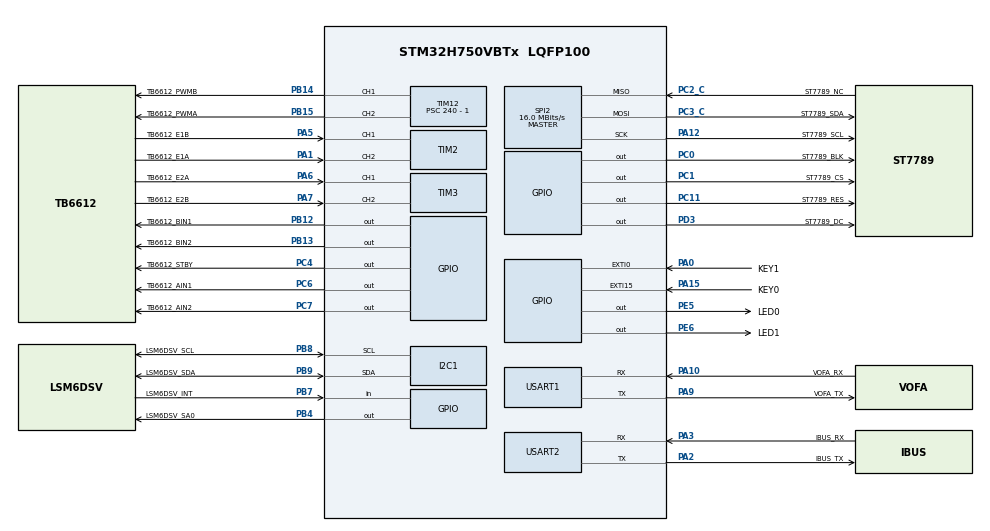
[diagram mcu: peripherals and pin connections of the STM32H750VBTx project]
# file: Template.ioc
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CORTEX_M7.BaseAddress-Cortex_Memory_Protection_Unit_Region0_Settings=0x2400000
CORTEX_M7.CPU_DCache=Disabled
CORTEX_M7.CPU_ICache=Disabled
CORTEX_M7.Enable-Cortex_Memory_Protection_Unit_Region0_Settings=MPU_REGION_ENABLE
CORTEX_M7.IsCacheable-Cortex_Memory_Protection_Unit_Region0_Settings=MPU_ACCESS_CACHEABLE
CORTEX_M7.IsShareable-Cortex_Memory_Protection_Unit_Region0_Settings=MPU_ACCESS_SHAREABLE
CORTEX_M7.MPU_Control=__NULL
CORTEX_M7.Size-Cortex_Memory_Protection_Unit_Region0_Settings=MPU_REGION_SIZE_512KB
CORTEX_M7.default_mode_Activation=0
Dma.Request0=SPI2_TX
Dma.Request1=SPI2_RX
Dma.SPI2_RX.1.Direction=DMA_PERIPH_TO_MEMORY
Dma.SPI2_RX.1.EventEnable=DISABLE
Dma.SPI2_RX.1.FIFOMode=DMA_FIFOMODE_DISABLE
Dma.SPI2_RX.1.Instance=DMA1_Stream1
Dma.SPI2_RX.1.MemDataAlignment=DMA_MDATAALIGN_BYTE
Dma.SPI2_RX.1.MemInc=DMA_MINC_ENABLE
Dma.SPI2_RX.1.Mode=DMA_NORMAL
Dma.SPI2_RX.1.PeriphDataAlignment=DMA_PDATAALIGN_BYTE
Dma.SPI2_RX.1.PeriphInc=DMA_PINC_DISABLE
Dma.SPI2_RX.1.Polarity=HAL_DMAMUX_REQ_GEN_RISING
Dma.SPI2_RX.1.Priority=DMA_PRIORITY_LOW
Dma.SPI2_RX.1.RequestNumber=1
Dma.SPI2_RX.1.SignalID=NONE
Dma.SPI2_RX.1.SyncEnable=DISABLE
Dma.SPI2_RX.1.SyncPolarity=HAL_DMAMUX_SYNC_NO_EVENT
Dma.SPI2_RX.1.SyncRequestNumber=1
Dma.SPI2_RX.1.SyncSignalID=NONE
Dma.SPI2_TX.0.Direction=DMA_MEMORY_TO_PERIPH
Dma.SPI2_TX.0.EventEnable=DISABLE
Dma.SPI2_TX.0.FIFOMode=DMA_FIFOMODE_DISABLE
Dma.SPI2_TX.0.Instance=DMA1_Stream0
Dma.SPI2_TX.0.MemDataAlignment=DMA_MDATAALIGN_BYTE
Dma.SPI2_TX.0.MemInc=DMA_MINC_ENABLE
Dma.SPI2_TX.0.Mode=DMA_NORMAL
Dma.SPI2_TX.0.PeriphDataAlignment=DMA_PDATAALIGN_BYTE
Dma.SPI2_TX.0.PeriphInc=DMA_PINC_DISABLE
Dma.SPI2_TX.0.Polarity=HAL_DMAMUX_REQ_GEN_RISING
Dma.SPI2_TX.0.Priority=DMA_PRIORITY_LOW
Dma.SPI2_TX.0.RequestNumber=1
Dma.SPI2_TX.0.SignalID=NONE
Dma.SPI2_TX.0.SyncEnable=DISABLE
Dma.SPI2_TX.0.SyncPolarity=HAL_DMAMUX_SYNC_NO_EVENT
Dma.SPI2_TX.0.SyncRequestNumber=1
Dma.SPI2_TX.0.SyncSignalID=NONE
FREERTOS.Tasks01=defaultTask,8,256,StartDefaultTask,Default,NULL,Dynamic,NULL,NULL;LightTask,8,128,StartLightTask,As weak,NULL,Dynamic,NULL,NULL;AttitudeTask,46,512,StartAttitudeTask,As weak,NULL,Dynamic,NULL,NULL;DisplayTask,8,256,StartDisplayTask,As weak,NULL,Dynamic,NULL,NULL;MotorTask,44,256,StartMotorTask,As weak,NULL,Dynamic,NULL,NULL;SpeedControlTas,45,256,StartSpeedControlTask,As weak,NULL,Dynamic,NULL,NULL;AngleControlTas,47,256,StartAngleControlTask,As weak,NULL,Dynamic,NULL,NULL;AngVelControlTa,48,256,StartAngVelControlTask,As weak,NULL,Dynamic,NULL,NULL;RemoteTask,24,256,StartRemoteTask,As weak,NULL,Dynamic,NULL,NULL
FREERTOS.configENABLE_FPU=1
I2C1.Timing=0x307075B1
Mcu.Family=STM32H7
Mcu.Name=STM32H750VBTx
Mcu.Package=LQFP100
NVIC.DMA1_Stream0_IRQn=true\:5\:0\:false\:false\:true\:true\:false\:true\:true
NVIC.DMA1_Stream1_IRQn=true\:5\:0\:false\:false\:true\:true\:false\:true\:true
NVIC.EXTI0_IRQn=true\:11\:0\:true\:false\:true\:true\:true\:true\:true
NVIC.EXTI15_10_IRQn=true\:11\:0\:true\:false\:true\:true\:true\:true\:true
NVIC.PriorityGroup=NVIC_PRIORITYGROUP_4
NVIC.SPI2_IRQn=true\:5\:0\:false\:false\:true\:true\:false\:true\:true
NVIC.TIM7_IRQn=true\:15\:0\:false\:false\:true\:false\:false\:true\:true
NVIC.TimeBase=TIM7_IRQn
NVIC.TimeBaseIP=TIM7
NVIC.USART1_IRQn=true\:5\:0\:false\:false\:true\:true\:true\:true\:true
NVIC.USART2_IRQn=true\:5\:0\:false\:false\:true\:true\:true\:true\:true
PA0.GPIO_Label=KEY1
PA0.GPIO_PuPd=GPIO_PULLDOWN
PA0.Signal=GPXTI0
PA1.GPIO_Label=TB6612_E1A
PA1.Signal=S_TIM2_CH2
PA10.GPIO_Label=VOFA_RX
PA10.GPIO_Speed=GPIO_SPEED_FREQ_VERY_HIGH
PA10.Mode=Asynchronous
PA10.Signal=USART1_RX
PA12.GPIO_Label=ST7789_SCL
PA12.Mode=Full_Duplex_Master
PA12.Signal=SPI2_SCK
PA13\ (JTMS/SWDIO).GPIO_Label=DAP_SWD
PA13\ (JTMS/SWDIO).Mode=Serial_Wire
PA13\ (JTMS/SWDIO).Signal=DEBUG_JTMS-SWDIO
PA14\ (JTCK/SWCLK).GPIO_Label=DAP_SCK
PA14\ (JTCK/SWCLK).Mode=Serial_Wire
PA14\ (JTCK/SWCLK).Signal=DEBUG_JTCK-SWCLK
PA15\ (JTDI).GPIO_Label=KEY0
PA15\ (JTDI).GPIO_PuPd=GPIO_PULLDOWN
PA15\ (JTDI).Signal=GPXTI15
PA2.GPIO_Label=IBUS_TX
PA2.Mode=Asynchronous
PA2.Signal=USART2_TX
PA3.GPIO_Label=IBUS_RX
PA3.GPIO_PuPd=GPIO_PULLUP
PA3.GPIO_Speed=GPIO_SPEED_FREQ_VERY_HIGH
PA3.Mode=Asynchronous
PA3.Signal=USART2_RX
PA5.GPIO_Label=TB6612_E1B
PA5.Signal=S_TIM2_CH1_ETR
PA6.GPIO_Label=TB6612_E2A
PA6.Signal=S_TIM3_CH1
PA7.GPIO_Label=TB6612_E2B
PA7.Signal=S_TIM3_CH2
PA9.GPIO_Label=VOFA_TX
PA9.GPIO_Speed=GPIO_SPEED_FREQ_VERY_HIGH
PA9.Mode=Asynchronous
PA9.Signal=USART1_TX
PB12.GPIO_Label=TB6612_BIN1
PB12.Signal=GPIO_Output
PB13.GPIO_Label=TB6612_BIN2
PB13.Signal=GPIO_Output
PB14.GPIO_Label=TB6612_PWMB
PB14.Signal=S_TIM12_CH1
PB15.GPIO_Label=TB6612_PWMA
PB15.Signal=S_TIM12_CH2
PB4\ (NJTRST).GPIO_Label=LSM6DSV_SA0
PB4\ (NJTRST).GPIO_PuPd=GPIO_PULLDOWN
PB4\ (NJTRST).PinState=GPIO_PIN_SET
PB4\ (NJTRST).Signal=GPIO_Output
PB7.GPIO_Label=LSM6DSV_INT
PB7.GPIO_PuPd=GPIO_PULLDOWN
PB7.Signal=GPIO_Input
PB8.GPIO_Label=LSM6DSV_SCL
PB8.GPIO_Mode=GPIO_MODE_AF_OD
PB8.GPIO_Pu=GPIO_PULLUP
PB8.GPIO_Speed=GPIO_SPEED_FREQ_VERY_HIGH
PB8.Mode=I2C
PB8.Signal=I2C1_SCL
PB9.GPIO_Label=LSM6DSV_SDA
PB9.GPIO_Mode=GPIO_MODE_AF_OD
PB9.GPIO_Pu=GPIO_PULLUP
PB9.GPIO_Speed=GPIO_SPEED_FREQ_VERY_HIGH
PB9.Mode=I2C
PB9.Signal=I2C1_SDA
PC0.GPIO_Label=ST7789_BLK
PC0.Signal=GPIO_Output
PC1.GPIO_Label=ST7789_CS
PC1.Signal=GPIO_Output
PC11.GPIO_Label=ST7789_RES
PC11.Signal=GPIO_Output
PC2_C.GPIO_Label=ST7789_NC
PC2_C.Mode=Full_Duplex_Master
PC2_C.Signal=SPI2_MISO
PC3_C.GPIO_Label=ST7789_SDA
PC3_C.Mode=Full_Duplex_Master
PC3_C.Signal=SPI2_MOSI
PC4.GPIO_Label=TB6612_STBY
PC4.Signal=GPIO_Output
PC6.GPIO_Label=TB6612_AIN1
PC6.Signal=GPIO_Output
PC7.GPIO_Label=TB6612_AIN2
PC7.Signal=GPIO_Output
PD3.GPIO_Label=ST7789_DC
PD3.Signal=GPIO_Output
PE5.GPIO_Label=LED0
PE5.GPIO_PuPd=GPIO_PULLDOWN
PE5.Signal=GPIO_Output
PE6.GPIO_Label=LED1
PE6.GPIO_PuPd=GPIO_PULLDOWN
PE6.Signal=GPIO_Output
PH0-OSC_IN\ (PH0).GPIO_Label=OSC_IN
PH0-OSC_IN\ (PH0).Mode=HSE-External-Oscillator
PH0-OSC_IN\ (PH0).Signal=RCC_OSC_IN
PH1-OSC_OUT\ (PH1).GPIO_Label=OSC_OUT
PH1-OSC_OUT\ (PH1).Mode=HSE-External-Oscillator
PH1-OSC_OUT\ (PH1).Signal=RCC_OSC_OUT
ProjectManager.HeapSize=0x2000
ProjectManager.StackSize=0x4000
ProjectManager.TargetToolchain=MDK-ARM V5.32
RCC.ADCFreq_Value=16125000
RCC.APB1Freq_Value=120000000
RCC.APB2Freq_Value=120000000
RCC.APB3Freq_Value=120000000
RCC.APB4Freq_Value=120000000
RCC.CortexFreq_Value=480000000
RCC.D1PPRE=RCC_APB3_DIV2
RCC.D2PPRE1=RCC_APB1_DIV2
RCC.D2PPRE2=RCC_APB2_DIV2
RCC.D3PPRE=RCC_APB4_DIV2
RCC.DIVM1=1
RCC.DIVN1=120
RCC.HCLKFreq_Value=240000000
RCC.HPRE=RCC_HCLK_DIV2
RCC.HSE_VALUE=8000000
RCC.PLL2FRACN=0
RCC.PLL3FRACN=0
RCC.PLLFRACN=0
RCC.PLLSourceVirtual=RCC_PLLSOURCE_HSE
RCC.SPI123CLockSelection=RCC_SPI123CLKSOURCE_CLKP
RCC.SYSCLKFreq_VALUE=480000000
RCC.SYSCLKSource=RCC_SYSCLKSOURCE_PLLCLK
RCC.USBFreq_Value=480000000
SH.S_TIM12_CH1.0=TIM12_CH1,PWM Generation1 CH1
SH.S_TIM12_CH2.0=TIM12_CH2,PWM Generation2 CH2
SH.S_TIM2_CH1_ETR.0=TIM2_CH1,Encoder_Interface
SH.S_TIM2_CH2.0=TIM2_CH2,Encoder_Interface
SH.S_TIM3_CH1.0=TIM3_CH1,Encoder_Interface
SH.S_TIM3_CH2.0=TIM3_CH2,Encoder_Interface
SPI2.BaudRatePrescaler=SPI_BAUDRATEPRESCALER_4
SPI2.CLKPolarity=SPI_POLARITY_HIGH
SPI2.CalculateBaudRate=16.0 MBits/s
SPI2.DataSize=SPI_DATASIZE_8BIT
SPI2.Direction=SPI_DIRECTION_2LINES
SPI2.Mode=SPI_MODE_MASTER
SPI2.VirtualType=VM_MASTER
TIM12.Channel-PWM\ Generation1\ CH1=TIM_CHANNEL_1
TIM12.Channel-PWM\ Generation2\ CH2=TIM_CHANNEL_2
TIM12.Prescaler=240 - 1
TIM15.Prescaler=240 - 1
USART1.VirtualMode-Asynchronous=VM_ASYNC
USART2.VirtualMode-Asynchronous=VM_ASYNC
VP_FREERTOS_VS_CMSIS_V2.Mode=CMSIS_V2
VP_MEMORYMAP_VS_MEMORYMAP.Mode=CurAppReg
VP_SYS_VS_tim7.Mode=TIM7
VP_TIM12_VS_ClockSourceINT.Mode=Internal
VP_TIM15_VS_ClockSourceINT.Mode=Internal
board=custom

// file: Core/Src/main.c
/* USER CODE BEGIN Header */
/**
  ******************************************************************************
  * @file           : main.c
  * @brief          : Main program body
  ******************************************************************************
  * @attention
  *
  * Copyright (c) 2025 STMicroelectronics.
  * All rights reserved.
  *
  * This software is licensed under terms that can be found in the LICENSE file
  * in the root directory of this software component.
  * If no LICENSE file comes with this software, it is provided AS-IS.
  *
  ******************************************************************************
  */
/* USER CODE END Header */
#include "main.h"
#include "cmsis_os.h"
#include "dma.h"
#include "i2c.h"
#include "spi.h"
#include "tim.h"
#include "usart.h"
#include "gpio.h"

/* USER CODE BEGIN Includes */
#include "stdio.h"
/* USER CODE END Includes */

void SystemClock_Config(void);
void PeriphCommonClock_Config(void);
void MX_FREERTOS_Init(void);
/* USER CODE BEGIN PFP */
void UART1_UserCallback(void *device_instance, uint16_t size);
/* USER CODE END PFP */

int main(void)
{

  /* MCU Configuration--------------------------------------------------------*/

  /* Reset of all peripherals, Initializes the Flash interface and the Systick. */
  HAL_Init();

  /* Configure the system clock */
  SystemClock_Config();

  /* Configure the peripherals common clocks */
  PeriphCommonClock_Config();

  /* Initialize all configured peripherals */
  MX_GPIO_Init();
  MX_DMA_Init();
  MX_USART1_UART_Init();
  MX_I2C1_Init();
  MX_TIM2_Init();
  MX_TIM3_Init();
  MX_TIM12_Init();
  MX_TIM15_Init();
  MX_SPI2_Init();
  MX_USART2_UART_Init();

  /* Init scheduler */
  osKernelInitialize();  /* Call init function for freertos objects (in cmsis_os2.c) */
  MX_FREERTOS_Init();

  /* Start scheduler */
  osKernelStart();

  /* We should never get here as control is now taken by the scheduler */

  /* Infinite loop */
  /* USER CODE BEGIN WHILE */
  while (1)
  {
    HAL_Delay(50);
    /* USER CODE END WHILE */

  }
}

void SystemClock_Config(void)
{
  RCC_OscInitTypeDef RCC_OscInitStruct = {0};
  RCC_ClkInitTypeDef RCC_ClkInitStruct = {0};

  /** Supply configuration update enable
  */
  HAL_PWREx_ConfigSupply(PWR_LDO_SUPPLY);

  /** Configure the main internal regulator output voltage
  */
  __HAL_PWR_VOLTAGESCALING_CONFIG(PWR_REGULATOR_VOLTAGE_SCALE0);

  while(!__HAL_PWR_GET_FLAG(PWR_FLAG_VOSRDY)) {}

  /** Initializes the RCC Oscillators according to the specified parameters
  * in the RCC_OscInitTypeDef structure.
  */
  RCC_OscInitStruct.OscillatorType = RCC_OSCILLATORTYPE_HSI|RCC_OSCILLATORTYPE_HSE;
  RCC_OscInitStruct.HSEState = RCC_HSE_ON;
  RCC_OscInitStruct.HSIState = RCC_HSI_DIV1;
  RCC_OscInitStruct.HSICalibrationValue = RCC_HSICALIBRATION_DEFAULT;
  RCC_OscInitStruct.PLL.PLLState = RCC_PLL_ON;
  RCC_OscInitStruct.PLL.PLLSource = RCC_PLLSOURCE_HSE;
  RCC_OscInitStruct.PLL.PLLM = 1;
  RCC_OscInitStruct.PLL.PLLN = 120;
  RCC_OscInitStruct.PLL.PLLP = 2;
  RCC_OscInitStruct.PLL.PLLQ = 2;
  RCC_OscInitStruct.PLL.PLLR = 2;
  RCC_OscInitStruct.PLL.PLLRGE = RCC_PLL1VCIRANGE_3;
  RCC_OscInitStruct.PLL.PLLVCOSEL = RCC_PLL1VCOWIDE;
  RCC_OscInitStruct.PLL.PLLFRACN = 0;
  if (HAL_RCC_OscConfig(&RCC_OscInitStruct) != HAL_OK)
  {
    Error_Handler();
  }

  /** Initializes the CPU, AHB and APB buses clocks
  */
  RCC_ClkInitStruct.ClockType = RCC_CLOCKTYPE_HCLK|RCC_CLOCKTYPE_SYSCLK
                              |RCC_CLOCKTYPE_PCLK1|RCC_CLOCKTYPE_PCLK2
                              |RCC_CLOCKTYPE_D3PCLK1|RCC_CLOCKTYPE_D1PCLK1;
  RCC_ClkInitStruct.SYSCLKSource = RCC_SYSCLKSOURCE_PLLCLK;
  RCC_ClkInitStruct.SYSCLKDivider = RCC_SYSCLK_DIV1;
  RCC_ClkInitStruct.AHBCLKDivider = RCC_HCLK_DIV2;
  RCC_ClkInitStruct.APB3CLKDivider = RCC_APB3_DIV2;
  RCC_ClkInitStruct.APB1CLKDivider = RCC_APB1_DIV2;
  RCC_ClkInitStruct.APB2CLKDivider = RCC_APB2_DIV2;
  RCC_ClkInitStruct.APB4CLKDivider = RCC_APB4_DIV2;

  if (HAL_RCC_ClockConfig(&RCC_ClkInitStruct, FLASH_LATENCY_4) != HAL_OK)
  {
    Error_Handler();
  }
}

void PeriphCommonClock_Config(void)
{
  RCC_PeriphCLKInitTypeDef PeriphClkInitStruct = {0};

  /** Initializes the peripherals clock
  */
  PeriphClkInitStruct.PeriphClockSelection = RCC_PERIPHCLK_CKPER;
  PeriphClkInitStruct.CkperClockSelection = RCC_CLKPSOURCE_HSI;
  if (HAL_RCCEx_PeriphCLKConfig(&PeriphClkInitStruct) != HAL_OK)
  {
    Error_Handler();
  }
}

void HAL_TIM_PeriodElapsedCallback(TIM_HandleTypeDef *htim)
{
  if (htim->Instance == TIM7)
  {
    HAL_IncTick();
  }
}

void Error_Handler(void)
{
  __disable_irq();
  while (1)
  {
  }
}

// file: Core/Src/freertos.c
/* USER CODE BEGIN Header */
/**
  ******************************************************************************
  * File Name          : freertos.c
  * Description        : Code for freertos applications
  ******************************************************************************
  * @attention
  *
  * Copyright (c) 2025 STMicroelectronics.
  * All rights reserved.
  *
  * This software is licensed under terms that can be found in the LICENSE file
  * in the root directory of this software component.
  * If no LICENSE file comes with this software, it is provided AS-IS.
  *
  ******************************************************************************
  */
/* USER CODE END Header */

#include "FreeRTOS.h"
#include "task.h"
#include "main.h"
#include "cmsis_os.h"

/* USER CODE BEGIN Includes */
#include "task_control.h"
#include "stdio.h"
#include "usart.h"
#include "task_attitude.h"
#include "task_motor.h"
/* USER CODE END Includes */

/* Definitions for defaultTask */
osThreadId_t defaultTaskHandle;
const osThreadAttr_t defaultTask_attributes = {
  .name = "defaultTask",
  .stack_size = 256 * 4,
  .priority = (osPriority_t) osPriorityLow,
};
/* Definitions for LightTask */
osThreadId_t LightTaskHandle;
const osThreadAttr_t LightTask_attributes = {
  .name = "LightTask",
  .stack_size = 128 * 4,
  .priority = (osPriority_t) osPriorityLow,
};
/* Definitions for AttitudeTask */
osThreadId_t AttitudeTaskHandle;
const osThreadAttr_t AttitudeTask_attributes = {
  .name = "AttitudeTask",
  .stack_size = 512 * 4,
  .priority = (osPriority_t) osPriorityHigh6,
};
/* Definitions for DisplayTask */
osThreadId_t DisplayTaskHandle;
const osThreadAttr_t DisplayTask_attributes = {
  .name = "DisplayTask",
  .stack_size = 256 * 4,
  .priority = (osPriority_t) osPriorityLow,
};
/* Definitions for MotorTask */
osThreadId_t MotorTaskHandle;
const osThreadAttr_t MotorTask_attributes = {
  .name = "MotorTask",
  .stack_size = 256 * 4,
  .priority = (osPriority_t) osPriorityHigh4,
};
/* Definitions for SpeedControlTas */
osThreadId_t SpeedControlTasHandle;
const osThreadAttr_t SpeedControlTas_attributes = {
  .name = "SpeedControlTas",
  .stack_size = 256 * 4,
  .priority = (osPriority_t) osPriorityHigh5,
};
/* Definitions for AngleControlTas */
osThreadId_t AngleControlTasHandle;
const osThreadAttr_t AngleControlTas_attributes = {
  .name = "AngleControlTas",
  .stack_size = 256 * 4,
  .priority = (osPriority_t) osPriorityHigh7,
};
/* Definitions for AngVelControlTa */
osThreadId_t AngVelControlTaHandle;
const osThreadAttr_t AngVelControlTa_attributes = {
  .name = "AngVelControlTa",
  .stack_size = 256 * 4,
  .priority = (osPriority_t) osPriorityRealtime,
};
/* Definitions for RemoteTask */
osThreadId_t RemoteTaskHandle;
const osThreadAttr_t RemoteTask_attributes = {
  .name = "RemoteTask",
  .stack_size = 256 * 4,
  .priority = (osPriority_t) osPriorityNormal,
};

void StartDefaultTask(void *argument);
void StartLightTask(void *argument);
void StartAttitudeTask(void *argument);
void StartDisplayTask(void *argument);
void StartMotorTask(void *argument);
void StartSpeedControlTask(void *argument);
void StartAngleControlTask(void *argument);
void StartAngVelControlTask(void *argument);
void StartRemoteTask(void *argument);

void MX_FREERTOS_Init(void); /* (MISRA C 2004 rule 8.1) */

void MX_FREERTOS_Init(void) {

  /* Create the thread(s) */
  /* creation of defaultTask */
  defaultTaskHandle = osThreadNew(StartDefaultTask, NULL, &defaultTask_attributes);

  /* creation of LightTask */
  LightTaskHandle = osThreadNew(StartLightTask, NULL, &LightTask_attributes);

  /* creation of AttitudeTask */
  AttitudeTaskHandle = osThreadNew(StartAttitudeTask, NULL, &AttitudeTask_attributes);

  /* creation of DisplayTask */
  DisplayTaskHandle = osThreadNew(StartDisplayTask, NULL, &DisplayTask_attributes);

  /* creation of MotorTask */
  MotorTaskHandle = osThreadNew(StartMotorTask, NULL, &MotorTask_attributes);

  /* creation of SpeedControlTas */
  SpeedControlTasHandle = osThreadNew(StartSpeedControlTask, NULL, &SpeedControlTas_attributes);

  /* creation of AngleControlTas */
  AngleControlTasHandle = osThreadNew(StartAngleControlTask, NULL, &AngleControlTas_attributes);

  /* creation of AngVelControlTa */
  AngVelControlTaHandle = osThreadNew(StartAngVelControlTask, NULL, &AngVelControlTa_attributes);

  /* creation of RemoteTask */
  RemoteTaskHandle = osThreadNew(StartRemoteTask, NULL, &RemoteTask_attributes);

}

void StartDefaultTask(void *argument)
{
  /* USER CODE BEGIN StartDefaultTask */

  /* Infinite loop */
  for(;;)
  {
    printf("%.4f,%.4f,%.4f,%.4f,%.4f,%.4f\r\n", turn_pid->p_out, turn_pid->i_out, turn_pid->d_out, turn_pid->output, target_speed, deltaspeed);
    // printf("%.4f,%.4f,%.4f,%.4f,%.4f,%.4f\r\n", speed_pid->p_out, speed_pid->i_out, speed_pid->d_out, speed_pid->output, speed, target_speed);
    // printf("%.2f,%.2f,%.2f,%.2f,%.2f,%.2f\r\n", angle_pid->p_out, angle_pid->i_out, angle_pid->d_out, angle_pid->output, pitch, target_speed);
    // printf("%.2f,%.2f,%.2f,%.2f,%.2f\r\n", angvel_pid->p_out, angvel_pid->i_out, angvel_pid->d_out, angvel_pid->output, lsm6dsv->gyro[0]);
    osDelay(10);
  }
  /* USER CODE END StartDefaultTask */
}

__weak void StartLightTask(void *argument)
{
  for(;;)
  {
    osDelay(1);
  }
}

__weak void StartAttitudeTask(void *argument)
{
  for(;;)
  {
    osDelay(1);
  }
}

__weak void StartDisplayTask(void *argument)
{
  for(;;)
  {
    osDelay(1);
  }
}

__weak void StartMotorTask(void *argument)
{
  for(;;)
  {
    osDelay(1);
  }
}

__weak void StartSpeedControlTask(void *argument)
{
  for(;;)
  {
    osDelay(1);
  }
}

__weak void StartAngleControlTask(void *argument)
{
  for(;;)
  {
    osDelay(1);
  }
}

__weak void StartAngVelControlTask(void *argument)
{
  for(;;)
  {
    osDelay(1);
  }
}

__weak void StartRemoteTask(void *argument)
{
  for(;;)
  {
    osDelay(1);
  }
}

/* USER CODE BEGIN Application */

int fputc(int ch, FILE *f)
{
  HAL_UART_Transmit(&huart1, (uint8_t *)&ch, 1, 0xffff);
  return ch;
}

/* USER CODE END Application */
